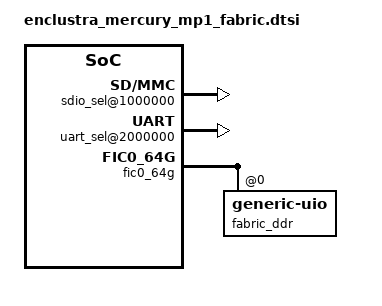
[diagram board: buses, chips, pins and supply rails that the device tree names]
// SPDX-License-Identifier: (GPL-2.0+ OR MIT)
/*
 * Copyright (C) 2022 Enclustra GmbH
 * <info@enclustra.com>
 */

#include "enclustra_mercury_mp1_common_fabric.dtsi"

&fic3_512m {
	gpio_led@0 {
		compatible = "generic-uio";
		linux,uio-name = "fic3-gpio-led";
		status = "okay";
		reg = <0x0 0x1000000>;
	};

	sdio_sel@1000000 {
		compatible = "generic-uio";
		linux,uio-name = "fic3-sdio-sel";
		status = "okay";
		reg = <0x1000000 0x1000000>;
	};

	uart_sel@2000000 {
		compatible = "generic-uio";
		linux,uio-name = "fic3-uart-sel";
		status = "okay";
		reg = <0x2000000 0x1000000>;
	};
};

&fic0_64g {
	/* 4 Gbyte DDR4 memory */
	fabric_ddr@0 {
		compatible = "generic-uio";
		linux,uio-name = "fic0-fabric-ddr";
		status = "okay";
		reg = <0x0 0x0 0x1 0x0>;
	};
};
